AUTOSAR XML (schema 00046)
package /ComponentTypes
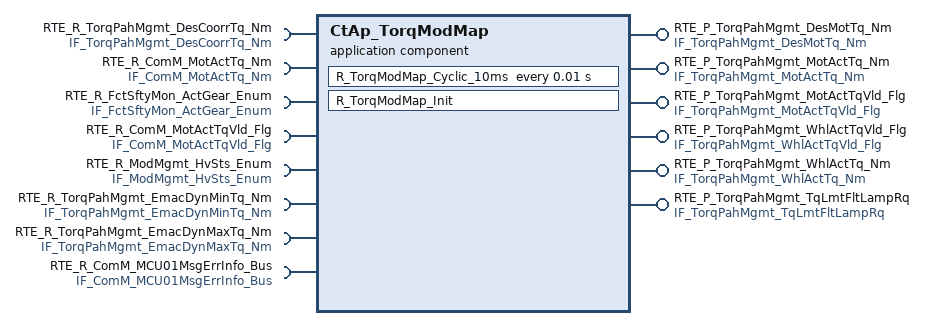
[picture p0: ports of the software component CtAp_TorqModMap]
  application sw component type CtAp_TorqModMap
    5 x provide port:
      RTE_P_TorqPahMgmt_DesMotTq_Nm: nonqueued-sender-com-spec{data-element=tec_TorqPahMgmt_DesMotTq_Nm, init-value=0}, provided-interface=IF_TorqPahMgmt_DesMotTq_Nm
      RTE_P_TorqPahMgmt_MotActTq_Nm: nonqueued-sender-com-spec{data-element=tec_TorqPahMgmt_MotActTq_Nm, init-value=0}, provided-interface=IF_TorqPahMgmt_MotActTq_Nm
      RTE_P_TorqPahMgmt_MotActTqVld_Flg: nonqueued-sender-com-spec{data-element=tec_TorqPahMgmt_MotActTqVld_Flg, init-value=0}, provided-interface=IF_TorqPahMgmt_MotActTqVld_Flg
      RTE_P_TorqPahMgmt_WhlActTqVld_Flg: nonqueued-sender-com-spec{data-element=tec_TorqPahMgmt_WhlActTqVld_Flg, init-value=0}, provided-interface=IF_TorqPahMgmt_WhlActTqVld_Flg
      RTE_P_TorqPahMgmt_WhlActTq_Nm: nonqueued-sender-com-spec{data-element=tec_TorqPahMgmt_WhlActTq_Nm, init-value=0}, provided-interface=IF_TorqPahMgmt_WhlActTq_Nm
    8 x require port:
      RTE_R_TorqPahMgmt_DesCoorrTq_Nm: nonqueued-receiver-com-spec{data-element=tec_TorqPahMgmt_DesCoorrTq_Nm, filter=data-filter-type=ALWAYS, init-value=0}, required-interface=IF_TorqPahMgmt_DesCoorrTq_Nm
      RTE_R_ComM_MotActTq_Nm: nonqueued-receiver-com-spec{data-element=tec_ComM_MotActTq_Nm, filter=data-filter-type=ALWAYS, init-value=0}, required-interface=IF_ComM_MotActTq_Nm
      RTE_R_FctSftyMon_ActGear_Enum: nonqueued-receiver-com-spec{data-element=tec_FctSftyMon_ActGear_Enum, filter=data-filter-type=ALWAYS, init-value=0}, required-interface=IF_FctSftyMon_ActGear_Enum
      RTE_R_ComM_MotActTqVld_Flg: nonqueued-receiver-com-spec{data-element=tec_ComM_MotActTqVld_Flg, filter=data-filter-type=ALWAYS, init-value=0}, required-interface=IF_ComM_MotActTqVld_Flg
      RTE_R_ModMgmt_HvSts_Enum: nonqueued-receiver-com-spec{data-element=tec_ModMgmt_HvSts_Enum, filter=data-filter-type=ALWAYS, init-value=0}, required-interface=IF_ModMgmt_HvSts_Enum
      RTE_R_TorqPahMgmt_EmacDynMinTq_Nm: nonqueued-receiver-com-spec{data-element=tec_TorqPahMgmt_EmacDynMinTq_Nm, filter=data-filter-type=ALWAYS, init-value=0}, required-interface=IF_TorqPahMgmt_EmacDynMinTq_Nm
      RTE_R_TorqPahMgmt_EmacDynMaxTq_Nm: nonqueued-receiver-com-spec{data-element=tec_TorqPahMgmt_EmacDynMaxTq_Nm, filter=data-filter-type=ALWAYS, init-value=0}, required-interface=IF_TorqPahMgmt_EmacDynMaxTq_Nm
      RTE_R_ComM_MCU01MsgErrInfo_Bus: required-interface=IF_ComM_MCU01MsgErrInfo_Bus
        required-com-specs:
          data-element=tec_ComM_MCU01TimeoutInfo_Bus, filter=data-filter-type=ALWAYS, init-value=fields=[ComM_MonStatMCU01TimeoutInfo:0, ComM_MonResMCU01TimeoutInfo:0, ComM_ErrStatMCU01TimeoutInfo:0, ComM_ErrResMCU01TimeoutInfo:0]
          data-element=tec_ComM_MCU01CRCDTCInfo_Bus, filter=data-filter-type=ALWAYS, init-value=fields=[ComM_MonStatMCU01CRCDTCErrorInfo:0, ComM_MonResMCU01CRCDTCErrorInfo:0, ComM_ErrStatMCU01CRCDTCErrorInfo:0, ComM_ErrResMCU01CRCDTCErrorInfo:0]
          data-element=tec_ComM_MCU01CRCInfo_Bus, filter=data-filter-type=ALWAYS, init-value=fields=[ComM_MonStatMCU01CRCErrorInfo:0, ComM_MonResMCU01CRCErrorInfo:0, ComM_ErrStatMCU01CRCErrorInfo:0, ComM_ErrResMCU01CRCErrorInfo:0]
          data-element=tec_ComM_MCU01TimeoutDTCInfo_Bus, filter=data-filter-type=ALWAYS, init-value=fields=[ComM_MonStatMCU01TimeoutDTCErrorInfo:0, ComM_MonResMCU01TimeoutDTCErrorInfo:0, ComM_ErrStatMCU01TimeoutDTCErrorInfo:0, ComM_ErrResMCU01TimeoutDTCErrorInfo:0]
          data-element=tec_ComM_MCU01E2ETimeoutInfo_Bus, filter=data-filter-type=ALWAYS, init-value=fields=[ComM_MonStatMCU01E2ETimeoutInfo:0, ComM_MonResMCU01E2ETimeoutInfo:0, ComM_ErrStatMCU01E2ETimeoutInfo:0, ComM_ErrResMCU01E2ETimeoutInfo:0]
    provide port RTE_P_TorqPahMgmt_TqLmtFltLampRq: nonqueued-sender-com-spec{data-element=tec_TorqPahMgmt_TqLmtFltLampRq, init-value=0}, provided-interface=IF_TorqPahMgmt_TqLmtFltLampRq
    behavior CtAp_TorqModMap_InternalBehavior
      timing event TMT_R_TorqModMap_Cyclic_10ms: start-on-event=R_TorqModMap_Cyclic_10ms, period=0.01
      init event CtAp_TorqModMap_InitEvent: start-on-event=R_TorqModMap_Init
      runnable R_TorqModMap_Cyclic_10ms
        data-receive-point-by-arguments:
          9 x access:
            REC_RTE_R_ComM_MotActTqVld_Flg_tec_ComM_MotActTqVld_Flg: accessed-variable=RTE_R_ComM_MotActTqVld_Flg.tec_ComM_MotActTqVld_Flg
            REC_RTE_R_ComM_MotActTq_Nm_tec_ComM_MotActTq_Nm: accessed-variable=RTE_R_ComM_MotActTq_Nm.tec_ComM_MotActTq_Nm
            REC_RTE_R_FctSftyMon_ActGear_Enum_tec_FctSftyMon_ActGear_Enum: accessed-variable=RTE_R_FctSftyMon_ActGear_Enum.tec_FctSftyMon_ActGear_Enum
            REC_RTE_R_ModMgmt_HvSts_Enum_tec_ModMgmt_HvSts_Enum: accessed-variable=RTE_R_ModMgmt_HvSts_Enum.tec_ModMgmt_HvSts_Enum
            REC_RTE_R_TorqPahMgmt_DesCoorrTq_Nm_tec_TorqPahMgmt_DesCoorrTq_Nm: accessed-variable=RTE_R_TorqPahMgmt_DesCoorrTq_Nm.tec_TorqPahMgmt_DesCoorrTq_Nm
            REC_RTE_R_TorqPahMgmt_EmacDynMaxTq_Nm_tec_TorqPahMgmt_EmacDynMaxTq_Nm: accessed-variable=RTE_R_TorqPahMgmt_EmacDynMaxTq_Nm.tec_TorqPahMgmt_EmacDynMaxTq_Nm
            REC_RTE_R_TorqPahMgmt_EmacDynMinTq_Nm_tec_TorqPahMgmt_EmacDynMinTq_Nm: accessed-variable=RTE_R_TorqPahMgmt_EmacDynMinTq_Nm.tec_TorqPahMgmt_EmacDynMinTq_Nm
            REC_RTE_R_ComM_MCU01MsgErrInfo_Bus_tec_ComM_MCU01CRCInfo_Bus: accessed-variable=RTE_R_ComM_MCU01MsgErrInfo_Bus.tec_ComM_MCU01CRCInfo_Bus
            REC_RTE_R_ComM_MCU01MsgErrInfo_Bus_tec_ComM_MCU01E2ETimeoutInfo_Bus: accessed-variable=RTE_R_ComM_MCU01MsgErrInfo_Bus.tec_ComM_MCU01E2ETimeoutInfo_Bus
        data-send-points:
          6 x access:
            SEND_RTE_P_TorqPahMgmt_DesMotTq_Nm_tec_TorqPahMgmt_DesMotTq_Nm: accessed-variable=RTE_P_TorqPahMgmt_DesMotTq_Nm.tec_TorqPahMgmt_DesMotTq_Nm
            SEND_RTE_P_TorqPahMgmt_MotActTqVld_Flg_tec_TorqPahMgmt_MotActTqVld_Flg: accessed-variable=RTE_P_TorqPahMgmt_MotActTqVld_Flg.tec_TorqPahMgmt_MotActTqVld_Flg
            SEND_RTE_P_TorqPahMgmt_MotActTq_Nm_tec_TorqPahMgmt_MotActTq_Nm: accessed-variable=RTE_P_TorqPahMgmt_MotActTq_Nm.tec_TorqPahMgmt_MotActTq_Nm
            SEND_RTE_P_TorqPahMgmt_WhlActTqVld_Flg_tec_TorqPahMgmt_WhlActTqVld_Flg: accessed-variable=RTE_P_TorqPahMgmt_WhlActTqVld_Flg.tec_TorqPahMgmt_WhlActTqVld_Flg
            SEND_RTE_P_TorqPahMgmt_WhlActTq_Nm_tec_TorqPahMgmt_WhlActTq_Nm: accessed-variable=RTE_P_TorqPahMgmt_WhlActTq_Nm.tec_TorqPahMgmt_WhlActTq_Nm
            SEND_RTE_P_TorqPahMgmt_TqLmtFltLampRq_tec_TorqPahMgmt_TqLmtFltLampRq: accessed-variable=RTE_P_TorqPahMgmt_TqLmtFltLampRq.tec_TorqPahMgmt_TqLmtFltLampRq
      runnable R_TorqModMap_Init
  swc implementation CtAp_TorqModMap_Implementation: behavior=CtAp_TorqModMap_InternalBehavior
